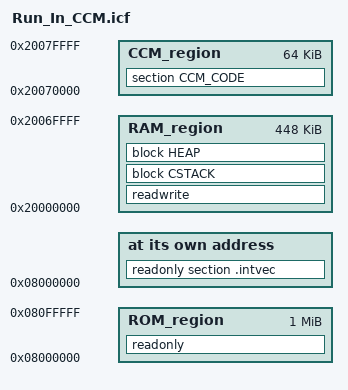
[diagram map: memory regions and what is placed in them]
/*###ICF### Section handled by ICF editor, don't touch! ****/
/*-Editor annotation file-*/
/* IcfEditorFile="$TOOLKIT_DIR$\config\ide\IcfEditor\cortex_v1_0.xml" */
/*
 * ICF file for Run_In_CCM demo
 *
 * Memory map:
 *   FLASH   : 0x08000000 - 0x080FFFFF (1024KB)
 *   SRAM1   : 0x20000000 - 0x2003FFFF ( 256KB)
 *   SRAM2   : 0x20040000 - 0x2006FFFF ( 192KB)
 *   CCM SRAM: 0x20070000 - 0x2007FFFF (64KB)
 *
 * CCM_CODE functions are stored in FLASH and copied to CCM SRAM at startup.
 * The C code does not need the FLASH load address; CCM_SRAM_SaveCode()
 * backs up the CCM bytes to a regular-SRAM buffer before CCM_SRAM_Init()
 * wipes CCM, and CCM_SRAM_RestoreCode() writes them back afterwards.
 */
/*-Specials-*/
define symbol __ICFEDIT_intvec_start__ = 0x08000000;
/*-Memory Regions-*/
define symbol __ICFEDIT_region_ROM_start__ = 0x08000000;
define symbol __ICFEDIT_region_ROM_end__   = 0x080FFFFF;
define symbol __ICFEDIT_region_RAM_start__ = 0x20000000;
define symbol __ICFEDIT_region_RAM_end__   = 0x2006FFFF;
define symbol __ICFEDIT_region_CCM_start__ = 0x20070000;
define symbol __ICFEDIT_region_CCM_end__   = 0x2007FFFF;
/*-Sizes-*/
define symbol __ICFEDIT_size_cstack__ = 0x1000;
define symbol __ICFEDIT_size_heap__   = 0x200;
/**** End of ICF editor section. ###ICF###*/

define memory mem with size = 4G;
define region ROM_region = mem:[from __ICFEDIT_region_ROM_start__ to __ICFEDIT_region_ROM_end__];
define region RAM_region = mem:[from __ICFEDIT_region_RAM_start__ to __ICFEDIT_region_RAM_end__];
define region CCM_region = mem:[from __ICFEDIT_region_CCM_start__ to __ICFEDIT_region_CCM_end__];

define block CSTACK with alignment = 8, size = __ICFEDIT_size_cstack__ { };
define block HEAP   with alignment = 8, size = __ICFEDIT_size_heap__   { };

/* Copy RW data and CCM code from FLASH to CCM SRAM at startup */
initialize by copy { readwrite };
initialize by copy { section CCM_CODE };
do not initialize  { section .noinit };

place at address mem:__ICFEDIT_intvec_start__ { readonly section .intvec };
place in ROM_region { readonly };
/* Execute CCM_CODE functions from CCM SRAM */
place in CCM_region { section CCM_CODE };
place in RAM_region { readwrite, block CSTACK, block HEAP };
